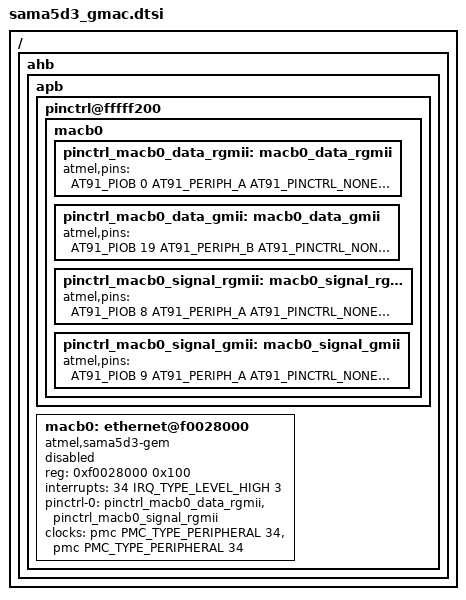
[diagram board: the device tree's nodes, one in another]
#include <dt-bindings/pinctrl/at91.h>
#include <dt-bindings/interrupt-controller/irq.h>
/ {
	ahb {
		apb {
			pinctrl@fffff200 {
				macb0 {
					pinctrl_macb0_data_rgmii: macb0_data_rgmii {
						atmel,pins =
							<AT91_PIOB 0 AT91_PERIPH_A AT91_PINCTRL_NONE	 
							 AT91_PIOB 1 AT91_PERIPH_A AT91_PINCTRL_NONE	 
							 AT91_PIOB 2 AT91_PERIPH_A AT91_PINCTRL_NONE	 
							 AT91_PIOB 3 AT91_PERIPH_A AT91_PINCTRL_NONE	 
							 AT91_PIOB 4 AT91_PERIPH_A AT91_PINCTRL_NONE	 
							 AT91_PIOB 5 AT91_PERIPH_A AT91_PINCTRL_NONE	 
							 AT91_PIOB 6 AT91_PERIPH_A AT91_PINCTRL_NONE	 
							 AT91_PIOB 7 AT91_PERIPH_A AT91_PINCTRL_NONE>;	 
					};
					pinctrl_macb0_data_gmii: macb0_data_gmii {
						atmel,pins =
							<AT91_PIOB 19 AT91_PERIPH_B AT91_PINCTRL_NONE	 
							 AT91_PIOB 20 AT91_PERIPH_B AT91_PINCTRL_NONE	 
							 AT91_PIOB 21 AT91_PERIPH_B AT91_PINCTRL_NONE	 
							 AT91_PIOB 22 AT91_PERIPH_B AT91_PINCTRL_NONE	 
							 AT91_PIOB 23 AT91_PERIPH_B AT91_PINCTRL_NONE	 
							 AT91_PIOB 24 AT91_PERIPH_B AT91_PINCTRL_NONE	 
							 AT91_PIOB 25 AT91_PERIPH_B AT91_PINCTRL_NONE	 
							 AT91_PIOB 26 AT91_PERIPH_B AT91_PINCTRL_NONE>;	 
					};
					pinctrl_macb0_signal_rgmii: macb0_signal_rgmii {
						atmel,pins =
							<AT91_PIOB 8 AT91_PERIPH_A AT91_PINCTRL_NONE	 
							 AT91_PIOB 9 AT91_PERIPH_A AT91_PINCTRL_NONE	 
							 AT91_PIOB 11 AT91_PERIPH_A AT91_PINCTRL_NONE	 
							 AT91_PIOB 13 AT91_PERIPH_A AT91_PINCTRL_NONE	 
							 AT91_PIOB 16 AT91_PERIPH_A AT91_PINCTRL_NONE	 
							 AT91_PIOB 17 AT91_PERIPH_A AT91_PINCTRL_NONE	 
							 AT91_PIOB 18 AT91_PERIPH_A AT91_PINCTRL_NONE>;	 
					};
					pinctrl_macb0_signal_gmii: macb0_signal_gmii {
						atmel,pins =
							<AT91_PIOB 9 AT91_PERIPH_A AT91_PINCTRL_NONE	 
							 AT91_PIOB 10 AT91_PERIPH_A AT91_PINCTRL_NONE	 
							 AT91_PIOB 11 AT91_PERIPH_A AT91_PINCTRL_NONE	 
							 AT91_PIOB 12 AT91_PERIPH_A AT91_PINCTRL_NONE	 
							 AT91_PIOB 13 AT91_PERIPH_A AT91_PINCTRL_NONE	 
							 AT91_PIOB 14 AT91_PERIPH_A AT91_PINCTRL_NONE	 
							 AT91_PIOB 15 AT91_PERIPH_A AT91_PINCTRL_NONE	 
							 AT91_PIOB 16 AT91_PERIPH_A AT91_PINCTRL_NONE	 
							 AT91_PIOB 17 AT91_PERIPH_A AT91_PINCTRL_NONE	 
							 AT91_PIOB 27 AT91_PERIPH_B AT91_PINCTRL_NONE>;	 
					};
				};
			};
			macb0: ethernet@f0028000 {
				compatible = "atmel,sama5d3-gem";
				reg = <0xf0028000 0x100>;
				interrupts = <34 IRQ_TYPE_LEVEL_HIGH 3>;
				pinctrl-names = "default";
				pinctrl-0 = <&pinctrl_macb0_data_rgmii &pinctrl_macb0_signal_rgmii>;
				clocks = <&pmc PMC_TYPE_PERIPHERAL 34>, <&pmc PMC_TYPE_PERIPHERAL 34>;
				clock-names = "hclk", "pclk";
				status = "disabled";
			};
		};
	};
};
